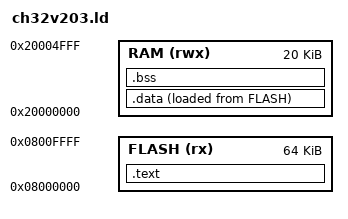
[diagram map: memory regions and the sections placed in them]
/* ch32v203.ld: CH32V203-like, 64K flash @0x08000000, 20K SRAM @0x20000000 */
ENTRY(_start)
MEMORY
{
    FLASH (rx)  : ORIGIN = 0x08000000, LENGTH = 64K
    RAM   (rwx) : ORIGIN = 0x20000000, LENGTH = 20K
}
_estack = ORIGIN(RAM) + LENGTH(RAM);
SECTIONS
{
    .text : { KEEP(*(.text.start)) *(.text*) *(.rodata*) *(.srodata*) . = ALIGN(4); } > FLASH
    _sidata = LOADADDR(.data);
    .data : { _sdata = .; *(.data*) *(.sdata*) . = ALIGN(4); _edata = .; } > RAM AT > FLASH
    .bss (NOLOAD) : { _sbss = .; *(.sbss*) *(.bss*) *(COMMON) . = ALIGN(4); _ebss = .; } > RAM
}
